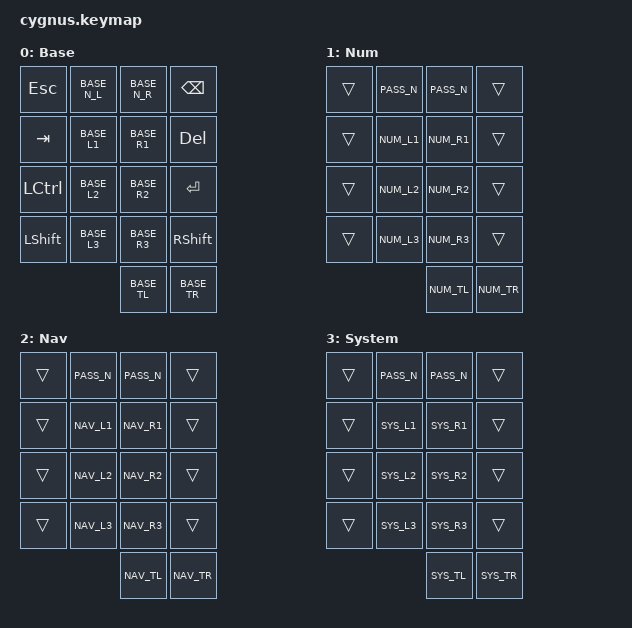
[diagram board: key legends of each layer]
// Dactyl Cygnus 4x6: the Corne 3x5 keymap (config/corne.keymap) plus the extra keys this board has.
// The behaviors and the layers' keys are shared with the other keyboards: config/common/.
//
// Key positions (4x6 + 3 thumbs):
//  0  1  2  3  4  5     6  7  8  9 10 11     number row (extra)
// 12 13 14 15 16 17    18 19 20 21 22 23     Q row (the Corne's top row, with an outer key each side)
// 24 25 26 27 28 29    30 31 32 33 34 35     A row
// 36 37 38 39 40 41    42 43 44 45 46 47     Z row
//          48 49 50    51 52 53              thumbs
//
// Extra keys: a number row on top, and an outer column on each side (Esc Tab Ctrl Shift on the left, Bksp Del
// Enter Shift on the right). The extras are transparent on the Num, Nav and System layers, so they keep working
// there.

#define HS_FOLLOW_POS 25                // A
#define HSP_FOLLOW_POS 46               // /
#define SYSTEM_COMBO_POSITIONS 52 53    // Enter and Backspace
#include "common/behaviors.dtsi"
#include "common/combos.dtsi"
#include "common/layers.dtsi"

// The extra keys (X = extra; 0 is the number row, then the Q, A and Z rows; L and R are the left and right edge)
#define BASE_X0_L &kp ESC
#define BASE_X0_R &kp BSPC
#define BASE_N_L &kp N1  &kp N2  &kp N3  &kp N4  &kp N5
#define BASE_N_R &kp N6  &kp N7  &kp N8  &kp N9  &kp N0
#define BASE_X1_L &kp TAB
#define BASE_X1_R &kp DEL
#define BASE_X2_L &kp LCTRL
#define BASE_X2_R &kp ENTER
#define BASE_X3_L &kp LSHFT
#define BASE_X3_R &kp RSHFT

#define PASS_N &trans  &trans  &trans  &trans  &trans
#define PASS &trans

/ {
    keymap {
        compatible = "zmk,keymap";

        default_layer {
            display-name = "Base";
            bindings = <
BASE_X0_L BASE_N_L    BASE_N_R BASE_X0_R
BASE_X1_L BASE_L1     BASE_R1  BASE_X1_R
BASE_X2_L BASE_L2     BASE_R2  BASE_X2_R
BASE_X3_L BASE_L3     BASE_R3  BASE_X3_R
                      BASE_TL  BASE_TR
            >;
        };

        num {
            display-name = "Num";
            bindings = <
PASS PASS_N    PASS_N PASS
PASS NUM_L1    NUM_R1 PASS
PASS NUM_L2    NUM_R2 PASS
PASS NUM_L3    NUM_R3 PASS
               NUM_TL NUM_TR
            >;
        };

        nav {
            display-name = "Nav";
            bindings = <
PASS PASS_N    PASS_N PASS
PASS NAV_L1    NAV_R1 PASS
PASS NAV_L2    NAV_R2 PASS
PASS NAV_L3    NAV_R3 PASS
               NAV_TL NAV_TR
            >;
        };

        system {
            display-name = "System";
            bindings = <
PASS PASS_N    PASS_N PASS
PASS SYS_L1    SYS_R1 PASS
PASS SYS_L2    SYS_R2 PASS
PASS SYS_L3    SYS_R3 PASS
               SYS_TL SYS_TR
            >;
        };
    };
};
